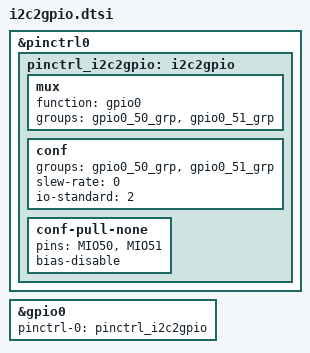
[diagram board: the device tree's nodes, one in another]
&pinctrl0 {
	pinctrl_i2c2gpio: i2c2gpio {
		mux {
			function = "gpio0";
			groups = "gpio0_50_grp", "gpio0_51_grp";
		};

		conf {
			groups = "gpio0_50_grp", "gpio0_51_grp";
			slew-rate = <0>;
			io-standard = <2>;  // LVCMOS25
		};

		conf-pull-none {
			pins = "MIO50", "MIO51";
			bias-disable;
		};
	};
};

&gpio0 {
	pinctrl-names = "default";
	pinctrl-0 = <&pinctrl_i2c2gpio>;
};
